# Z20K14xM register map
Vendor: Zhixin Semiconductor; Series: Z20K14xM; File version: 0.1.0
CPU: CM4 r0p1, little endian, no MPU, FPU, 4 interrupt priority bits
Registers are 32-bit, read-write, reset 0x0 unless marked. A register's access mark holds for its fields unless they carry their own. Offsets are from the block's base; [hi:lo] are bit positions; {n}, {i} and the like mark numbered series.

## AES
Base 0x400332000
0x00 AES_VERSION reset 0x20110091 — Version register
  [31:0] VERSION — Version number of the IP
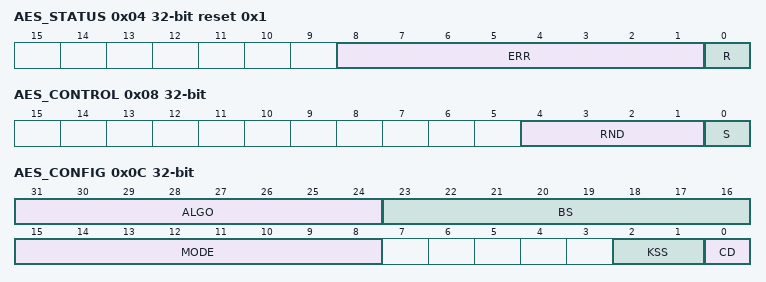
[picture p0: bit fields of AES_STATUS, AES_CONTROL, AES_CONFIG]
0x04 AES_STATUS reset 0x1 — Status register
  [8:1] ERR — error code
  [0] R — R ready bit
0x08 AES_CONTROL — Control register
  [4:1] RND — 4-bit random data
  [0] S — operation start bit
0x0C AES_CONFIG — Config register
  [31:24] ALGO — Reserved
  [23:16] BS — Block Size
  [15:8] MODE — operation mode
  [2:1] KSS — Reserved
  [0] CD — operation command
{0x1C+4i} AES_DATA_I{i} (i=0..3) — Data input {i} registers.
  [31:0] DATA_I — data input
{0x2C+4i} AES_DATA_O{i} (i=0..3) — Data output {i} registers.
  [31:0] DATA_O — data output
{0x3C+4i} AES_KEY{i} (i=0..3) — Key {i} registers.
  [31:0] KEY{i} — input KEY {i}
{0x5C+4i} AES_IV{i} (i=0..3) — Initialization Vector (IV) input {i} registers.
  [31:0] IV{i} — Initialization Vector {i}

## CMU0
Base 0x4003E000
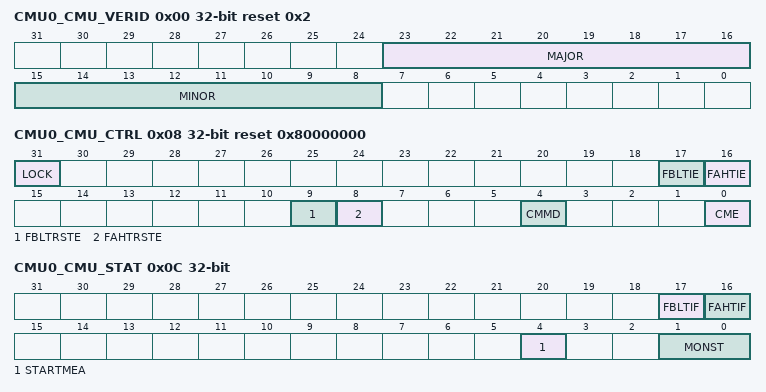
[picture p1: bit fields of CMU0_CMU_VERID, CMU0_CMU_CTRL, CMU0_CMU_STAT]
0x00 CMU0_CMU_VERID ro reset 0x2 — Clock Monitor Unit Version Idenfication(CMU_VERID)
  [23:16] MAJOR — Major version
  [15:8] MINOR — Minor version
0x04 CMU0_CMU_PARAM ro reset 0x1 — Clock Monitor Unit Parameter(CMU_PARAM)
  [0] RST_IMP — Reset generation implemented
0x08 CMU0_CMU_CTRL reset 0x80000000 — Clock Monitor Unit Control(CMU_CTRL)
  [31] LOCK — Write register lock
  [17] FBLTIE — Frequency Below Low Threshold Interrupt Enable
  [16] FAHTIE — Frequency Above High Threshold Interrupt Enable
  [9] FBLTRSTE — Frequency Below Low Threshold Reset Enable
  [8] FAHTRSTE — Frequency Above High Threshold Reset Enable
  [4] CMMD — Clock Monitor Mode
  [0] CME — Clock Monitor Enable
0x0C CMU0_CMU_STAT — Clock Monitor Unit Status(CMU_STAT)
  [17] FBLTIF — Frequency Below Low Threshold Interrupt Flag
  [16] FAHTIF — Frequency Above High Threshold Interrupt Flag
  [4] STARTMEA — Start to measure
  [1:0] MONST — Monitor State
0x10 CMU0_CMU_MONWIN — Clock Monitor Unit Monitor Window(CMU_MONWIN)
  [31:0] MONWIN — Monitor Window
0x14 CMU0_CMU_CUMHCT4INT — Clock Monitor Unit Clock Under Monitor High Compare Threshold For Interrupt(CMU_CUMHCT4INT)
  [31:0] HCT4INT — High Compare Threshold For Interrupt
0x18 CMU0_CMU_CUMLCT4INT — Clock Monitor Unit Clock Under Monitor Low Compare Threshold For Interrupt(CMU_CUMLCT4INT)
  [31:0] LCT4INT — Low Compare Threshold For Interrupt
0x1C CMU0_CMU_CUMHCT4RST — Clock Monitor Unit Clock Under Monitor High Compare Threshold For Reset(CMU_CUMHCT4RST)
  [31:0] HCT4RST — High Compare Threshold For Reset
0x20 CMU0_CMU_CUMLCT4RST — Clock Monitor Unit Clock Under Monitor Low Compare Threshold For Reset(CMU_CUMLCT4RST)
  [31:0] LCT4RST — Low Compare Threshold For Reset
0x24 CMU0_CMU_CUMMEARSLT — Clock Monitor Unit Clock Under Monitor Measurement Result
  [31:0] MEARSLT — Measurement result

## CMU1
Base 0x40042000
Registers as CMU0 (with CMU0 read as CMU1).

## CMU2
Base 0x40043000
Registers as CMU0 (with CMU0 read as CMU2).

## STIM
Base 0x40040000
0x00 STIM_VERID ro reset 0x2 — stim version ID register(STIM_VERID)
  [31:0] VERID — Version ID
{0x4+4i} STIM_CNTn{i} ro (i=0..3) — stim channel n counter register(STIM_CNTn)
  [31:0] CNT — 32-bit counter
{0x14+4i} STIM_CVn{i} (i=0..3) — stim channel n compare value register(STIM_CVn)
  [31:0] CV — stim compare value
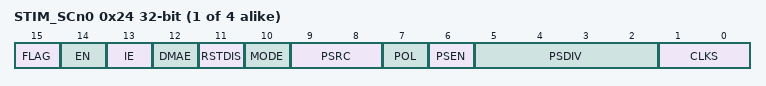
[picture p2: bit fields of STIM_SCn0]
{0x24+4i} STIM_SCn{i} (i=0..3) — stim channel n status and control register(STIM_SCn)
  [15] FLAG — timer flag
  [14] EN — stim enable
  [13] IE — interrupt enable
  [12] DMAE — dma enable
  [11] RSTDIS — counter reset disable on match
  [10] MODE — timer mode select
  [9:8] PSRC — input pin source select
  [7] POL — input pin polarity
  [6] PSEN — Prescaler/Glitch filter enable
  [5:2] PSDIV — Prescaler divider factor/Glitch filter value
  [1:0] CLKS — clock source select
